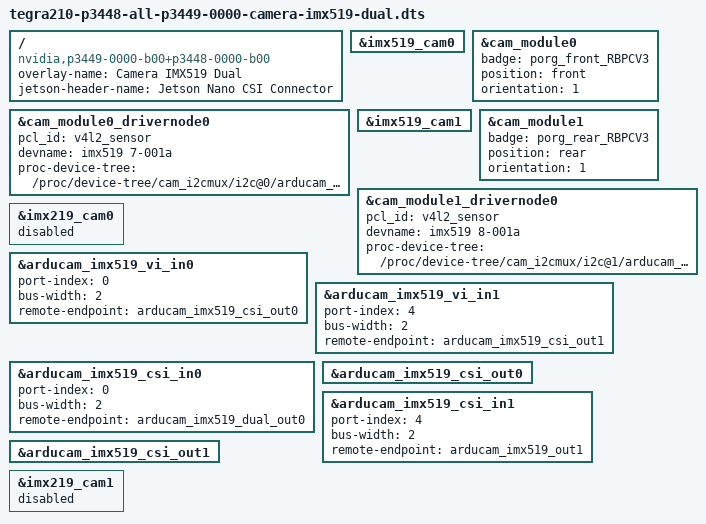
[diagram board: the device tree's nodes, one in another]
// SPDX-License-Identifier: GPL-2.0-only
/*
 * Jetson Device-tree overlay for Camera IMX519 for t210 single
 * cam connector baseboards
 *
 * Copyright (c) 2021, Arducam Technology co., Ltd.  All rights reserved.
 * 
 * Based on tegra210-p3448-all-p3449-0000-camera-imx477-dual.dts
 * Copyright (c) 2021 NVIDIA CORPORATION. All rights reserved.
 *
 */

/dts-v1/;
/plugin/;

/ {
	overlay-name = "Camera IMX519 Dual";
	jetson-header-name = "Jetson Nano CSI Connector";
	compatible = "nvidia,p3449-0000-b00+p3448-0000-b00", "nvidia,p3449-0000-b00+p3448-0002-b00";

	/* IMX519 dual sensor module */
	fragment@0 {
		target = <&imx519_cam0>;
		__overlay__ {
			status = "okay";
		};
	};
	fragment@1 {
		target = <&cam_module0>;
		__overlay__ {
			status = "okay";
			badge = "porg_front_RBPCV3";
			position = "front";
			orientation = "1";
		};
	};
	fragment@2 {
		target = <&cam_module0_drivernode0>;
		__overlay__ {
			status = "okay";
			pcl_id = "v4l2_sensor";
			devname = "imx519 7-001a";
			proc-device-tree = "/proc/device-tree/cam_i2cmux/i2c@0/arducam_imx519_a@1a";
		};
	};
	fragment@3 {
		target = <&imx519_cam1>;
		__overlay__ {
			status = "okay";
		};
	};
	fragment@4 {
		target = <&cam_module1>;
		__overlay__ {
			status = "okay";
			badge = "porg_rear_RBPCV3";
			position = "rear";
			orientation = "1";
		};
	};
	fragment@5 {
		target = <&cam_module1_drivernode0>;
		__overlay__ {
			status = "okay";
			pcl_id = "v4l2_sensor";
			devname = "imx519 8-001a";
			proc-device-tree = "/proc/device-tree/cam_i2cmux/i2c@1/arducam_imx519_e@1a";
		};
	};
	fragment@6 {
		target = <&imx219_cam0>;
		__overlay__ {
			status = "disabled";
		};
	};

	fragment@7 {
		target = <&arducam_imx519_vi_in0>;
		__overlay__ {
			status = "okay";
			port-index = <0>;
			bus-width = <2>;
			remote-endpoint = <&arducam_imx519_csi_out0>;
		};
	};
	fragment@8 {
		target = <&arducam_imx519_vi_in1>;
		__overlay__ {
			status = "okay";
			port-index = <4>;
			bus-width = <2>;
			remote-endpoint = <&arducam_imx519_csi_out1>;
		};
	};
	fragment@9 {
		target = <&arducam_imx519_csi_in0>;
		__overlay__ {
			status = "okay";
			port-index = <0>;
			bus-width = <2>;
			remote-endpoint = <&arducam_imx519_dual_out0>;
		};
	};
	fragment@10 {
		target = <&arducam_imx519_csi_out0>;
		__overlay__ {
			status = "okay";
		};
	};
	fragment@11 {
		target = <&arducam_imx519_csi_in1>;
		__overlay__ {
			status = "okay";
			port-index = <4>;
			bus-width = <2>;
			remote-endpoint = <&arducam_imx519_out1>;
		};
	};
	fragment@12 {
		target = <&arducam_imx519_csi_out1>;
		__overlay__ {
			status = "okay";
		};
	};
	fragment@13 {
		target = <&imx219_cam1>;
		__overlay__ {
			status = "disabled";
		};
	};
};
